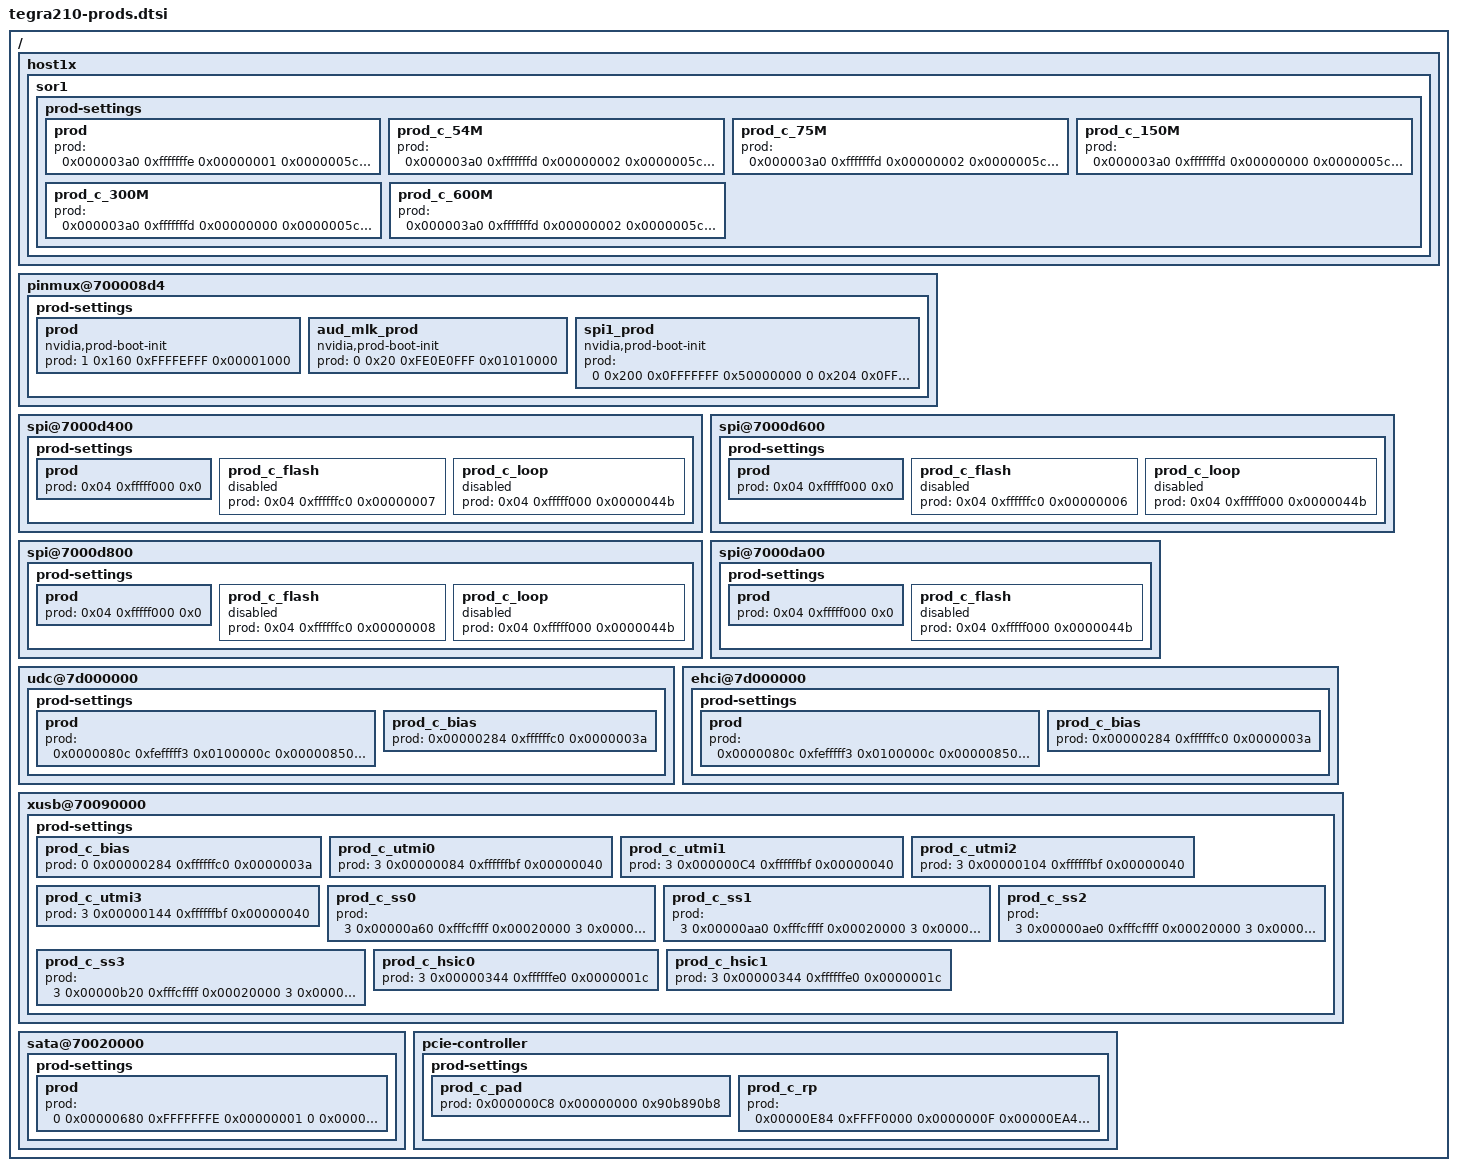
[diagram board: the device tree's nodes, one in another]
/*
 * Copyright (c) 2014-2015, NVIDIA CORPORATION.  All rights reserved.
 *
 * This program is free software; you can redistribute it and/or modify
 * it under the terms of the GNU General Public License as published by
 * the Free Software Foundation; version 2 of the License.
 *
 * This program is distributed in the hope that it will be useful, but WITHOUT
 * ANY WARRANTY; without even the implied warranty of MERCHANTABILITY or
 * FITNESS FOR A PARTICULAR PURPOSE.  See the GNU General Public License for
 * more details.
 *
 * You should have received a copy of the GNU General Public License along
 * with this program; if not, write to the Free Software Foundation, Inc.,
 * 51 Franklin Street, Fifth Floor, Boston, MA  02110-1301, USA.
 *
 */

/ {
	host1x {
		sor1 {
			prod-settings {
				prod {
				    prod = <
					0x000003a0 0xfffffffe 0x00000001	// SOR_NV_PDISP_INPUT_CONTROL  	00:00=HDMI_SRC_SELECT	0x1
					0x0000005c 0xf0fff8ff 0x01000000	// SOR_NV_PDISP_SOR_PLL0_0	11:08=VCOCAP		0x0
										//				27:24=ICHPMP		0x1
					0x00000060 0xff0fe0ff 0x00300f80	// SOR_NV_PDISP_SOR_PLL1_0	08:08=TMDS_TERM		0x1
										//				12:09=TMDS_TERMADJ	0xf
										//				23:20=LOADADJ		0x3
					0x00000068 0xf0ffffff 0x09000000	// SOR_NV_PSIDP_SOR_PLL3_0	27:24=BG_VREF_LEVEL	0x9
					0x00000138 0x00000000 0x373f3f3f	// SOR_NV_PDISP_SOR_LANE_DRIVE_CURRENT0_0
										//				31:24=LANE3_DP_LANE3	0x37
										//				23:16=LANE2_DP_LANE0	0x3f
										//				15:08=LANE1_DP_LANE1	0x3f
										//				07:00=LANE0_DP_LANE2	0x3f
					0x00000148 0x00000000 0x00000000	// SOR_NV_PDISP_SOR_LANE_PREEMPHASIS0_0
										//				31:24=LANE3_DP_LANE3	0x00
										//				23:16=LANE2_DP_LANE0	0x00
										//				15:08=LANE1_DP_LANE1	0x00
										//				07:00=LANE0_DP_LANE2	0x00
					0x00000170 0xffbf00ff 0x00401000	// SOR_NV_PDISP_SOR_DP_PADCTL0_0
										//				22:22=TX_PU		0x1
										//				15:08=TX_PU_VALUE	0x10
				   >;
				};
				prod_c_54M {
				    prod = <
					0x000003a0 0xfffffffd 0x00000002	// SOR_NV_PDISP_INPUT_CONTROL  	01:01=ARM_VIDEO_RANGE	0x1
					0x0000005c 0xf0fff8ff 0x01000000	// SOR_NV_PDISP_SOR_PLL0_0	11:08=VCOCAP		0x0
										//				27:24=ICHPMP		0x1
					0x00000060 0xff0fe0ff 0x00300f80	// SOR_NV_PDISP_SOR_PLL1_0	08:08=TMDS_TERM		0x1
										//				12:09=TMDS_TERMADJ	0xf
										//				23:20=LOADADJ		0x3
					0x00000068 0xf0ffffff 0x09000000	// SOR_NV_PSIDP_SOR_PLL3_0	27:24=BG_VREF_LEVEL	0x9
					0x00000138 0x00000000 0x373f3f3f	// SOR_NV_PDISP_SOR_LANE_DRIVE_CURRENT0_0
										//				31:24=LANE3_DP_LANE3	0x37
										//				23:16=LANE2_DP_LANE0	0x3f
										//				15:08=LANE1_DP_LANE1	0x3f
										//				07:00=LANE0_DP_LANE2	0x3f
					0x00000148 0x00000000 0x00000000	// SOR_NV_PDISP_SOR_LANE_PREEMPHASIS0_0
										//				31:24=LANE3_DP_LANE3	0x00
										//				23:16=LANE2_DP_LANE0	0x00
										//				15:08=LANE1_DP_LANE1	0x00
										//				07:00=LANE0_DP_LANE2	0x00
					0x00000170 0xffbf00ff 0x00401000	// SOR_NV_PDISP_SOR_DP_PADCTL0_0
										//				22:22=TX_PU		0x1
										//				15:08=TX_PU_VALUE	0x10
				   >;
				};
				prod_c_75M {
				    prod = <
					0x000003a0 0xfffffffd 0x00000002	// SOR_NV_PDISP_INPUT_CONTROL  	01:01=ARM_VIDEO_RANGE	0x1
					0x0000005c 0xf0fff8ff 0x01000100	// SOR_NV_PDISP_SOR_PLL0_0	11:08=VCOCAP		0x1
										//				27:24=ICHPMP		0x1
					0x00000060 0xff0fe0ff 0x00300f80	// SOR_NV_PDISP_SOR_PLL1_0	08:08=TMDS_TERM		0x1
										//				12:09=TMDS_TERMADJ	0x9
										//				23:20=LOADADJ		0x3
					0x00000068 0xf0ffffff 0x09000000	// SOR_NV_PSIDP_SOR_PLL3_0	27:24=BG_VREF_LEVEL	0x9
					0x00000138 0x00000000 0x33373737	// SOR_NV_PDISP_SOR_LANE_DRIVE_CURRENT0_0
										//				31:24=LANE3_DP_LANE3	0x33
										//				23:16=LANE2_DP_LANE0	0x37
										//				15:08=LANE1_DP_LANE1	0x37
										//				07:00=LANE0_DP_LANE2	0x37
					0x00000148 0x00000000 0x00000000	// SOR_NV_PDISP_SOR_LANE_PREEMPHASIS0_0
										//				31:24=LANE3_DP_LANE3	0x00
										//				23:16=LANE2_DP_LANE0	0x00
										//				15:08=LANE1_DP_LANE1	0x00
										//				07:00=LANE0_DP_LANE2	0x00
					0x00000170 0xffbf00ff 0x00404000	// SOR_NV_PDISP_SOR_DP_PADCTL0_0
										//				22:22=TX_PU		0x1
										//				15:08=TX_PU_VALUE	0x40

				    >;
				};
				prod_c_150M {
				    prod = <
					0x000003a0 0xfffffffd 0x00000000	// SOR_NV_PDISP_INPUT_CONTROL  	01:01=ARM_VIDEO_RANGE	0x0
					0x0000005c 0xf0fff8ff 0x01000300	// SOR_NV_PDISP_SOR_PLL0_0	11:08=VCOCAP		0x3
										//				27:24=ICHPMP		0x1
					0x00000060 0xff0fe0ff 0x00300980	// SOR_NV_PDISP_SOR_PLL1_0	08:08=TMDS_TERM		0x1
										//				12:09=TMDS_TERMADJ	0x9
										//				23:20=LOADADJ		0x3
					0x00000068 0xf0ffffff 0x08000000	// SOR_NV_PSIDP_SOR_PLL3_0	27:24=BG_VREF_LEVEL	0x8
					0x00000138 0x00000000 0x33373737	// SOR_NV_PDISP_SOR_LANE_DRIVE_CURRENT0_0
										//				31:24=LANE3_DP_LANE3	0x33
										//				23:16=LANE2_DP_LANE0	0x3f
										//				15:08=LANE1_DP_LANE1	0x3f
										//				07:00=LANE0_DP_LANE2	0x3f
					0x00000148 0x00000000 0x00000000	// SOR_NV_PDISP_SOR_LANE_PREEMPHASIS0_0
										//				31:24=LANE3_DP_LANE3	0x00
										//				23:16=LANE2_DP_LANE0	0x00
										//				15:08=LANE1_DP_LANE1	0x00
										//				07:00=LANE0_DP_LANE2	0x00
					0x00000170 0xffbf00ff 0x00406600	// SOR_NV_PDISP_SOR_DP_PADCTL0_0
										//				22:22=TX_PU		0x1
										//				15:08=TX_PU_VALUE	0x66
				    >;
				};
				prod_c_300M {
				    prod = <
					0x000003a0 0xfffffffd 0x00000000	// SOR_NV_PDISP_INPUT_CONTROL  	01:01=ARM_VIDEO_RANGE	0x0
					0x0000005c 0xf0fff8ff 0x01000300	// SOR_NV_PDISP_SOR_PLL0_0	11:08=VCOCAP		0x3
										//				27:24=ICHPMP		0x1
					0x00000060 0xff0fe0ff 0x00300980	// SOR_NV_PDISP_SOR_PLL1_0	08:08=TMDS_TERM		0x1
										//				12:09=TMDS_TERMADJ	0x9
										//				23:20=LOADADJ		0x3
					0x00000068 0xf0ffffff 0x08000000	// SOR_NV_PSIDP_SOR_PLL3_0	27:24=BG_VREF_LEVEL	0x8
					0x00000138 0x00000000 0x33373737	// SOR_NV_PDISP_SOR_LANE_DRIVE_CURRENT0_0
										//				31:24=LANE3_DP_LANE3	0x33
										//				23:16=LANE2_DP_LANE0	0x37
										//				15:08=LANE1_DP_LANE1	0x37
										//				07:00=LANE0_DP_LANE2	0x37
					0x00000148 0x00000000 0x00171717	// SOR_NV_PDISP_SOR_LANE_PREEMPHASIS0_0
										//				31:24=LANE3_DP_LANE3	0x00
										//				23:16=LANE2_DP_LANE0	0x17
										//				15:08=LANE1_DP_LANE1	0x17
										//				07:00=LANE0_DP_LANE2	0x17
					0x00000170 0xffbf00ff 0x00406600	// SOR_NV_PDISP_SOR_DP_PADCTL0_0
										//				22:22=TX_PU		0x1
										//				15:08=TX_PU_VALUE	0x66
				    >;
				};
				prod_c_600M {
				    prod = <
					0x000003a0 0xfffffffd 0x00000002	// SOR_NV_PDISP_INPUT_CONTROL  	01:01=ARM_VIDEO_RANGE	0x1
					0x0000005c 0xf0fff8ff 0x01000300	// SOR_NV_PDISP_SOR_PLL0_0	11:08=VCOCAP		0x3
										//				27:24=ICHPMP		0x1
					0x00000060 0xff0fe0ff 0x00300980	// SOR_NV_PDISP_SOR_PLL1_0	08:08=TMDS_TERM		0x1
										//				12:09=TMDS_TERMADJ	0x9
										//				23:20=LOADADJ		0x3
					0x00000068 0xf0ffffff 0x08000000	// SOR_NV_PSIDP_SOR_PLL3_0	27:24=BG_VREF_LEVEL	0x8
					0x00000138 0x00000000 0x33373737	// SOR_NV_PDISP_SOR_LANE_DRIVE_CURRENT0_0
										//				31:24=LANE3_DP_LANE3	0x33
										//				23:16=LANE2_DP_LANE0	0x3f
										//				15:08=LANE1_DP_LANE1	0x3f
										//				07:00=LANE0_DP_LANE2	0x3f
					0x00000148 0x00000000 0x00000000	// SOR_NV_PDISP_SOR_LANE_PREEMPHASIS0_0
										//				31:24=LANE3_DP_LANE3	0x00
										//				23:16=LANE2_DP_LANE0	0x00
										//				15:08=LANE1_DP_LANE1	0x00
										//				07:00=LANE0_DP_LANE2	0x00
					0x00000170 0xffbf00ff 0x00406600	// SOR_NV_PDISP_SOR_DP_PADCTL0_0
										//				22:22=TX_PU		0x1
										//				15:08=TX_PU_VALUE	0x66
				   >;
				};
			};
		};
	};

	pinmux@700008d4 {
		prod-settings {
			#prod-cells = <4>;
			prod {
				status = "okay";
				nvidia,prod-boot-init;
				prod = <1 0x160 0xFFFFEFFF 0x00001000>;
			};

			aud_mlk_prod {
				status = "okay";
				nvidia,prod-boot-init;
				prod = <0 0x20 0xFE0E0FFF 0x01010000>;
			};
			spi1_prod {
				nvidia,prod-boot-init;
				prod = <0 0x200 0x0FFFFFFF 0x50000000
					0 0x204 0x0FFFFFFF 0x50000000
					0 0x208 0x0FFFFFFF 0x50000000
					0 0x20c 0x0FFFFFFF 0x50000000
					0 0x210 0x0FFFFFFF 0x50000000>;
			};
		};
	};

	spi@7000d400 {
		prod-settings {
			prod {
			    prod = <0x04 0xfffff000 0x0>;
			};
			prod_c_flash {
			    status = "disabled";
			    /* enabled for spi flash rom */
			    prod = <0x04 0xffffffc0 0x00000007>;
			};
			prod_c_loop {
			    status = "disabled";
			    /* enabled for spi loopback mode */
			    prod = <0x04 0xfffff000 0x0000044b>;
			};
		};
	};
	spi@7000d600 {
		prod-settings {
			prod {
			    prod = <0x04 0xfffff000 0x0>;
			};
			prod_c_flash {
			    status = "disabled";
			    /* enabled for spi flash rom */
			    prod = <0x04 0xffffffc0 0x00000006>;
			};
			prod_c_loop {
			    status = "disabled";
			    /* enabled for spi loopback mode */
			    prod = <0x04 0xfffff000 0x0000044b>;
			};
		};
	};
	spi@7000d800 {
		prod-settings {
			prod {
			    prod = <0x04 0xfffff000 0x0>;
			};
			prod_c_flash {
			    status = "disabled";
			    /* enabled for spi flash rom */
			    prod = <0x04 0xffffffc0 0x00000008>;
			};
			prod_c_loop {
			    status = "disabled";
			    /* enabled for spi loopback mode */
			    prod = <0x04 0xfffff000 0x0000044b>;
			};
		};
	};
	spi@7000da00 {
		prod-settings {
			prod {
			    prod = <0x04 0xfffff000 0x0>;
			};
			prod_c_flash {
			    status = "disabled";
			    /* enabled for spi loopback mode */
			    prod = <0x04 0xfffff000 0x0000044b>;
			};
		};
	};

	udc@7d000000 {
		prod-settings {
				#prod-cells = <3>;
				prod {
					prod = <0x0000080c 0xfefffff3 0x0100000c// UTMIP_BIAS_CFG0
										//				24:24=HS_DISCON_LEVEL_MSB	0x03
										//				3:2=HS_DISCON_LEVEL_LSB		0x01
						0x00000850 0xfffffffe 0x00000002// UTMIP_BIAS_CFG2_0
										//				2:0=HSSQUELCH_LEVEL_NEW		0x02
						0x00000810 0xf0ffffff 0x00000000// UTMIP_HSRX_CFG0
										// 				27:24=UTMIP_PCOUNT_UPDN_DIV	0x00
					>;
				};
				prod_c_bias {
					prod = <0x00000284 0xffffffc0 0x0000003a
					>;
				};
		};
	};

	ehci@7d000000 {
		prod-settings {
				#prod-cells = <3>;
				prod {
					prod = <0x0000080c 0xfefffff3 0x0100000c// UTMIP_BIAS_CFG0
										//				24:24=HS_DISCON_LEVEL_MSB	0x01
										//				3:2=HS_DISCON_LEVEL_LSB		0x03
						0x00000850 0xfffffffe 0x00000002// UTMIP_BIAS_CFG2_0
										//				2:0=HSSQUELCH_LEVEL_NEW		0x02
					>;
				};
				prod_c_bias {
					prod = <0x00000284 0xffffffc0 0x0000003a
					>;
				};
		};
	};

	xusb@70090000 {
		prod-settings {
			#prod-cells = <4>;
			prod_c_bias {
			    prod = <
				0 0x00000284 0xffffffc0 0x0000003a
			    >;
			};
			prod_c_utmi0 {
			    prod = <
				3 0x00000084 0xffffffbf 0x00000040
			    >;
			};
			prod_c_utmi1 {
			    prod = <
				3 0x000000C4 0xffffffbf 0x00000040
			    >;
			};
			prod_c_utmi2 {
			    prod = <
				3 0x00000104 0xffffffbf 0x00000040
			    >;
			};
			prod_c_utmi3 {
			    prod = <
				3 0x00000144 0xffffffbf 0x00000040
			    >;
			};
			prod_c_ss0 {
			    prod = <
				3 0x00000a60 0xfffcffff 0x00020000
				3 0x00000a64 0xffff0000 0x000000fc
				3 0x00000a68 0x00000000 0xc0077f1f
				3 0x00000a74 0x00000000 0xfcf01368
			    >;
			};
			prod_c_ss1 {
			    prod = <
				3 0x00000aa0 0xfffcffff 0x00020000
				3 0x00000aa4 0xffff0000 0x000000fc
				3 0x00000aa8 0x00000000 0xc0077f1f
				3 0x00000ab4 0x00000000 0xfcf01368
			    >;
			};
			prod_c_ss2 {
			    prod = <
				3 0x00000ae0 0xfffcffff 0x00020000
				3 0x00000ae4 0xffff0000 0x000000fc
				3 0x00000ae8 0x00000000 0xc0077f1f
				3 0x00000af4 0x00000000 0xfcf01368
			    >;
			};
			prod_c_ss3 {
			    prod = <
				3 0x00000b20 0xfffcffff 0x00020000
				3 0x00000b24 0xffff0000 0x000000fc
				3 0x00000b28 0x00000000 0xc0077f1f
				3 0x00000b34 0x00000000 0xfcf01368
			    >;
			};
			prod_c_hsic0 {
			    prod = <
				3 0x00000344 0xffffffe0 0x0000001c
			    >;
			};
			prod_c_hsic1 {
			    prod = <
				3 0x00000344 0xffffffe0 0x0000001c
			    >;
			};
		};
	};
        sata@70020000 {
                prod-settings {
                        #prod-cells = <4>;
                        prod {
                                prod = <
                                        0 0x00000680 0xFFFFFFFE 0x00000001      // SATA_CHX_INDEX_0             0
                                        0 0x00000690 0xFFFFF000 0x00000715      // SATA_CHX_PHY_CTRL1_GEN1_0    31:0
                                        0 0x00000694 0xFFF00F00 0x0000E01B      // SATA_CHX_PHY_CTRL1_GEN2_0    31:0
                                        0 0x000006d0 0x00000000 0x00AB000F      // SATA_CHX_PHY_CTRL11_0        31:0
                                >;
                        };
                };
        };
	pcie-controller {
		prod-settings {
			prod_c_pad {
				prod = <
					0x000000C8 0x00000000 0x90b890b8	// PADS_REFCLK_CFG0		31:0	 0x90b890b8
				>;
			};
			prod_c_rp {
				prod = <
					0x00000E84 0xFFFF0000 0x0000000F	// RP_ECTL_2_R1_0	15:0=RX_CTLE_1C		0x000F
					0x00000EA4 0xFFFF0000 0x0000008F	// RP_ECTL_2_R2_0	15:0=RX_CTLE_1C		0x008F
					0x00000E90 0x00000000 0x55010000	// RP_ECTL_5_R1_0	31:0=RX_EQ_CTRL_L_1C	0x55010000
					0x00000E94 0x00000000 0x00000001	// RP_ECTL_6_R1_0	31:0=RX_EQ_CTRL_H_1C	0x00000001
					0x00000EB0 0x00000000 0x55010000	// RP_ECTL_5_R2_0	31:0=RX_EQ_CTRL_L_1C	0x55010000
					0x00000EB4 0x00000000 0x00000001	// RP_ECTL_6_R2_0	31:0=RX_EQ_CTRL_H_1C	0x00000001
					0x00000E8C 0x0000FFFF 0x00670000	// RP_ECTL_4_R1_0	31:16=RX_CDR_CTRL_1C	0x0067
					0x00000EAC 0x0000FFFF 0x00C70000	// RP_ECTL_4_R2_0	31:16=RX_CDR_CTRL_1C	0x00C7
				>;
			};
		};
	};

};
